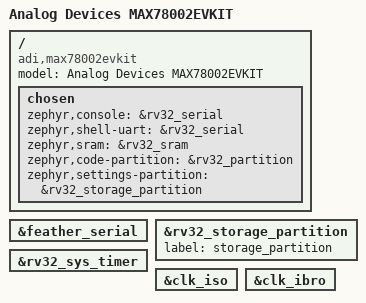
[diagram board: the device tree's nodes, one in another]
/*
 * Copyright (c) 2026 Analog Devices, Inc.
 *
 * SPDX-License-Identifier: Apache-2.0
 */

/dts-v1/;

#include <adi/max32/max78000-rv32.dtsi>
#include "max78000fthr.dtsi"

#include <adi/max32/max78000-pinctrl.dtsi>

/* Assign the RV32 core console to the Feather serial pins */
rv32_serial: &feather_serial {};

&rv32_storage_partition {
	label = "storage_partition";
};

/ {
	model = "Analog Devices MAX78002EVKIT";
	compatible = "adi,max78002evkit";

	chosen {
		zephyr,console = &rv32_serial;
		zephyr,shell-uart = &rv32_serial;
		zephyr,sram = &rv32_sram;
		zephyr,code-partition = &rv32_partition;
		zephyr,settings-partition = &rv32_storage_partition;
	};
};

&rv32_sys_timer {
	status = "okay";
};

&clk_iso {
	status = "okay";
};

&clk_ibro {
	status = "okay";
};

&rv32_serial {
	status = "okay";
};
